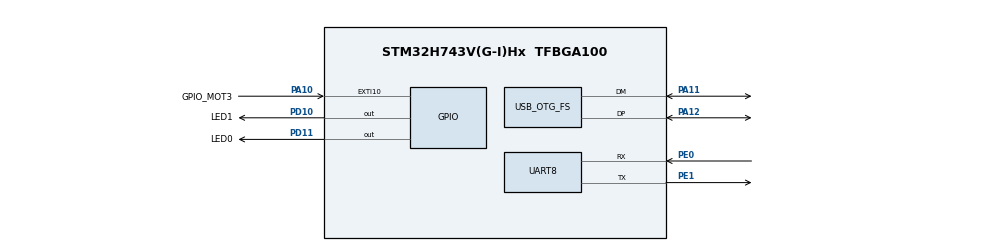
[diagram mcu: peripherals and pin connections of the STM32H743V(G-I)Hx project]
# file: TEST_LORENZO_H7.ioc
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CORTEX_M7.default_mode_Activation=1
Dma.Request0=UART8_RX
Dma.UART8_RX.0.Direction=DMA_PERIPH_TO_MEMORY
Dma.UART8_RX.0.EventEnable=DISABLE
Dma.UART8_RX.0.FIFOMode=DMA_FIFOMODE_DISABLE
Dma.UART8_RX.0.Instance=DMA1_Stream0
Dma.UART8_RX.0.MemDataAlignment=DMA_MDATAALIGN_BYTE
Dma.UART8_RX.0.MemInc=DMA_MINC_ENABLE
Dma.UART8_RX.0.Mode=DMA_CIRCULAR
Dma.UART8_RX.0.PeriphDataAlignment=DMA_PDATAALIGN_BYTE
Dma.UART8_RX.0.PeriphInc=DMA_PINC_DISABLE
Dma.UART8_RX.0.Polarity=HAL_DMAMUX_REQ_GEN_RISING
Dma.UART8_RX.0.Priority=DMA_PRIORITY_LOW
Dma.UART8_RX.0.RequestNumber=1
Dma.UART8_RX.0.SignalID=NONE
Dma.UART8_RX.0.SyncEnable=DISABLE
Dma.UART8_RX.0.SyncPolarity=HAL_DMAMUX_SYNC_NO_EVENT
Dma.UART8_RX.0.SyncRequestNumber=1
Dma.UART8_RX.0.SyncSignalID=NONE
FREERTOS.INCLUDE_uxTaskGetStackHighWaterMark2=1
FREERTOS.Tasks01=maintask,0,256,Startmaintask,Default,NULL,Dynamic,NULL,NULL;lidarparse,-3,500,Startlidarparse,Default,NULL,Dynamic,NULL,NULL
FREERTOS.configUSE_NEWLIB_REENTRANT=1
Mcu.Family=STM32H7
Mcu.Name=STM32H743V(G-I)Hx
Mcu.Package=TFBGA100
NVIC.DMA1_Stream0_IRQn=true\:5\:0\:false\:false\:true\:true\:false\:true\:true
NVIC.OTG_FS_IRQn=true\:5\:0\:false\:false\:true\:true\:false\:true\:true
NVIC.PriorityGroup=NVIC_PRIORITYGROUP_4
NVIC.TIM1_UP_IRQn=true\:15\:0\:false\:false\:true\:false\:false\:true\:true
NVIC.TimeBase=TIM1_UP_IRQn
NVIC.TimeBaseIP=TIM1
PA10.GPIO_Label=GPIO_MOT3
PA10.Signal=GPXTI10
PA11.Mode=Device_Only
PA11.Signal=USB_OTG_FS_DM
PA12.Mode=Device_Only
PA12.Signal=USB_OTG_FS_DP
PA13\ (JTMS/SWDIO).Mode=Serial_Wire
PA13\ (JTMS/SWDIO).Signal=DEBUG_JTMS-SWDIO
PA14\ (JTCK/SWCLK).Mode=Serial_Wire
PA14\ (JTCK/SWCLK).Signal=DEBUG_JTCK-SWCLK
PA15\ (JTDI).Signal=SPI1_NSS
PA8.Signal=I2C3_SCL
PB1.Signal=S_TIM3_CH4
PB10.Signal=I2C2_SCL
PB11.Signal=I2C2_SDA
PB14.Signal=USART1_TX
PB15.Signal=USART1_RX
PB3\ (JTDO/TRACESWO).Signal=SPI1_SCK
PB4\ (NJTRST).Signal=SPI1_MISO
PB7.Signal=S_TIM4_CH2
PB8.Signal=I2C1_SCL
PB9.Signal=I2C1_SDA
PC6.Signal=USART6_TX
PC7.Signal=USART6_RX
PC9.Signal=I2C3_SDA
PD0.Signal=SAI3_SCK_A
PD1.Signal=SAI3_SD_A
PD10.GPIO_Label=LED1
PD10.Signal=GPIO_Output
PD11.GPIO_Label=LED0
PD11.Signal=GPIO_Output
PD12.Signal=I2C4_SCL
PD13.Signal=I2C4_SDA
PD4.Signal=SAI3_FS_A
PD8.Signal=USART3_TX
PD9.Signal=USART3_RX
PE0.Mode=Asynchronous
PE0.Signal=UART8_RX
PE1.Mode=Asynchronous
PE1.Signal=UART8_TX
PE2.Signal=SPI4_SCK
PE5.Signal=SPI4_MISO
PE6.Signal=SPI4_MOSI
PE7.Signal=UART7_RX
PE8.Signal=UART7_TX
PH0-OSC_IN\ (PH0).Mode=HSE-External-Oscillator
PH0-OSC_IN\ (PH0).Signal=RCC_OSC_IN
PH1-OSC_OUT\ (PH1).Mode=HSE-External-Oscillator
PH1-OSC_OUT\ (PH1).Signal=RCC_OSC_OUT
ProjectManager.HeapSize=0x200
ProjectManager.StackSize=0x400
ProjectManager.TargetToolchain=STM32CubeIDE
RCC.ADCFreq_Value=75000000
RCC.APB1Freq_Value=120000000
RCC.APB2Freq_Value=120000000
RCC.APB3Freq_Value=120000000
RCC.APB4Freq_Value=120000000
RCC.CortexFreq_Value=480000000
RCC.D1PPRE=RCC_APB3_DIV2
RCC.D2PPRE1=RCC_APB1_DIV2
RCC.D2PPRE2=RCC_APB2_DIV2
RCC.D3PPRE=RCC_APB4_DIV2
RCC.DIVM1=1
RCC.DIVM2=8
RCC.DIVM3=2
RCC.DIVN1=120
RCC.DIVN2=150
RCC.DIVN3=130
RCC.DIVP3=10
RCC.HCLKFreq_Value=240000000
RCC.HPRE=RCC_HCLK_DIV2
RCC.HSE_VALUE=8000000
RCC.PLL2FRACN=0
RCC.PLL3FRACN=0
RCC.PLLFRACN=0
RCC.PLLSourceVirtual=RCC_PLLSOURCE_HSE
RCC.SAI23CLockSelection=RCC_SAI23CLKSOURCE_PLL2
RCC.SPI123CLockSelection=RCC_SPI123CLKSOURCE_PLL3
RCC.SYSCLKFreq_VALUE=480000000
RCC.SYSCLKSource=RCC_SYSCLKSOURCE_PLLCLK
RCC.USBCLockSelection=RCC_USBCLKSOURCE_HSI48
RCC.USBFreq_Value=48000000
SH.S_TIM3_CH4.0=TIM3_CH4
SH.S_TIM4_CH2.0=TIM4_CH2
USB_DEVICE.CLASS_NAME_FS=CDC
USB_DEVICE.VirtualMode-CDC_FS=Cdc
USB_DEVICE.VirtualModeFS=Cdc_FS
USB_OTG_FS.VirtualMode=Device_Only
VP_FREERTOS_VS_CMSIS_V1.Mode=CMSIS_V1
VP_MEMORYMAP_VS_MEMORYMAP.Mode=CurAppReg
VP_SYS_VS_tim1.Mode=TIM1
VP_USB_DEVICE_VS_USB_DEVICE_CDC_FS.Mode=CDC_FS
board=custom

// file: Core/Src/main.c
/* USER CODE BEGIN Header */
/**
  ******************************************************************************
  * @file           : main.c
  * @brief          : Main program body
  ******************************************************************************
  * @attention
  *
  * Copyright (c) 2025 STMicroelectronics.
  * All rights reserved.
  *
  * This software is licensed under terms that can be found in the LICENSE file
  * in the root directory of this software component.
  * If no LICENSE file comes with this software, it is provided AS-IS.
  *
  ******************************************************************************
  */
/* USER CODE END Header */
#include "main.h"
#include "cmsis_os.h"
#include "dma.h"
#include "usart.h"
#include "usb_device.h"
#include "gpio.h"

/* USER CODE BEGIN Includes */
#include "ylidar.h"
/* USER CODE END Includes */

/* USER CODE BEGIN PV */
extern uint8_t ylidar_circular_buffer[YLIDAR_CIRC_BUF_SIZE];
/* USER CODE END PV */

void SystemClock_Config(void);
static void MPU_Config(void);
void MX_FREERTOS_Init(void);

int main(void)
{

  /* MPU Configuration--------------------------------------------------------*/
  MPU_Config();

  /* MCU Configuration--------------------------------------------------------*/

  /* Reset of all peripherals, Initializes the Flash interface and the Systick. */
  HAL_Init();

  /* Configure the system clock */
  SystemClock_Config();

  /* Initialize all configured peripherals */
  MX_GPIO_Init();
  MX_DMA_Init();
  MX_UART8_Init();
  /* USER CODE BEGIN 2 */

  HAL_UART_Abort(&huart8);
  HAL_UART_Receive_DMA(&huart8, (uint8_t *)ylidar_circular_buffer, YLIDAR_CIRC_BUF_SIZE);
  __HAL_DMA_ENABLE_IT(huart8.hdmarx,DMA_IT_HT);

  /* USER CODE END 2 */

  /* Call init function for freertos objects (in cmsis_os2.c) */
  MX_FREERTOS_Init();

  /* Start scheduler */
  osKernelStart();

  /* We should never get here as control is now taken by the scheduler */

  /* Infinite loop */
  while (1)
  {

  }
}

void SystemClock_Config(void)
{
  RCC_OscInitTypeDef RCC_OscInitStruct = {0};
  RCC_ClkInitTypeDef RCC_ClkInitStruct = {0};

  /** Supply configuration update enable
  */
  HAL_PWREx_ConfigSupply(PWR_LDO_SUPPLY);

  /** Configure the main internal regulator output voltage
  */
  __HAL_PWR_VOLTAGESCALING_CONFIG(PWR_REGULATOR_VOLTAGE_SCALE0);

  while(!__HAL_PWR_GET_FLAG(PWR_FLAG_VOSRDY)) {}

  /** Initializes the RCC Oscillators according to the specified parameters
  * in the RCC_OscInitTypeDef structure.
  */
  RCC_OscInitStruct.OscillatorType = RCC_OSCILLATORTYPE_HSI48|RCC_OSCILLATORTYPE_HSE;
  RCC_OscInitStruct.HSEState = RCC_HSE_ON;
  RCC_OscInitStruct.HSI48State = RCC_HSI48_ON;
  RCC_OscInitStruct.PLL.PLLState = RCC_PLL_ON;
  RCC_OscInitStruct.PLL.PLLSource = RCC_PLLSOURCE_HSE;
  RCC_OscInitStruct.PLL.PLLM = 1;
  RCC_OscInitStruct.PLL.PLLN = 120;
  RCC_OscInitStruct.PLL.PLLP = 2;
  RCC_OscInitStruct.PLL.PLLQ = 2;
  RCC_OscInitStruct.PLL.PLLR = 2;
  RCC_OscInitStruct.PLL.PLLRGE = RCC_PLL1VCIRANGE_3;
  RCC_OscInitStruct.PLL.PLLVCOSEL = RCC_PLL1VCOWIDE;
  RCC_OscInitStruct.PLL.PLLFRACN = 0;
  if (HAL_RCC_OscConfig(&RCC_OscInitStruct) != HAL_OK)
  {
    Error_Handler();
  }

  /** Initializes the CPU, AHB and APB buses clocks
  */
  RCC_ClkInitStruct.ClockType = RCC_CLOCKTYPE_HCLK|RCC_CLOCKTYPE_SYSCLK
                              |RCC_CLOCKTYPE_PCLK1|RCC_CLOCKTYPE_PCLK2
                              |RCC_CLOCKTYPE_D3PCLK1|RCC_CLOCKTYPE_D1PCLK1;
  RCC_ClkInitStruct.SYSCLKSource = RCC_SYSCLKSOURCE_PLLCLK;
  RCC_ClkInitStruct.SYSCLKDivider = RCC_SYSCLK_DIV1;
  RCC_ClkInitStruct.AHBCLKDivider = RCC_HCLK_DIV2;
  RCC_ClkInitStruct.APB3CLKDivider = RCC_APB3_DIV2;
  RCC_ClkInitStruct.APB1CLKDivider = RCC_APB1_DIV2;
  RCC_ClkInitStruct.APB2CLKDivider = RCC_APB2_DIV2;
  RCC_ClkInitStruct.APB4CLKDivider = RCC_APB4_DIV2;

  if (HAL_RCC_ClockConfig(&RCC_ClkInitStruct, FLASH_LATENCY_4) != HAL_OK)
  {
    Error_Handler();
  }
}

 /* MPU Configuration */

void MPU_Config(void)
{
  MPU_Region_InitTypeDef MPU_InitStruct = {0};

  /* Disables the MPU */
  HAL_MPU_Disable();

  /** Initializes and configures the Region and the memory to be protected
  */
  MPU_InitStruct.Enable = MPU_REGION_ENABLE;
  MPU_InitStruct.Number = MPU_REGION_NUMBER0;
  MPU_InitStruct.BaseAddress = 0x0;
  MPU_InitStruct.Size = MPU_REGION_SIZE_4GB;
  MPU_InitStruct.SubRegionDisable = 0x87;
  MPU_InitStruct.TypeExtField = MPU_TEX_LEVEL0;
  MPU_InitStruct.AccessPermission = MPU_REGION_NO_ACCESS;
  MPU_InitStruct.DisableExec = MPU_INSTRUCTION_ACCESS_DISABLE;
  MPU_InitStruct.IsShareable = MPU_ACCESS_SHAREABLE;
  MPU_InitStruct.IsCacheable = MPU_ACCESS_NOT_CACHEABLE;
  MPU_InitStruct.IsBufferable = MPU_ACCESS_NOT_BUFFERABLE;

  HAL_MPU_ConfigRegion(&MPU_InitStruct);
  /* Enables the MPU */
  HAL_MPU_Enable(MPU_PRIVILEGED_DEFAULT);

}

void HAL_TIM_PeriodElapsedCallback(TIM_HandleTypeDef *htim)
{
  if (htim->Instance == TIM1)
  {
    HAL_IncTick();
  }
}

void Error_Handler(void)
{
  __disable_irq();
  while (1)
  {
  }
}

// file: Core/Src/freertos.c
/* USER CODE BEGIN Header */
/**
  ******************************************************************************
  * File Name          : freertos.c
  * Description        : Code for freertos applications
  ******************************************************************************
  * @attention
  *
  * Copyright (c) 2025 STMicroelectronics.
  * All rights reserved.
  *
  * This software is licensed under terms that can be found in the LICENSE file
  * in the root directory of this software component.
  * If no LICENSE file comes with this software, it is provided AS-IS.
  *
  ******************************************************************************
  */
/* USER CODE END Header */

#include "FreeRTOS.h"
#include "task.h"
#include "main.h"
#include "cmsis_os.h"

/* USER CODE BEGIN Includes */
#include "ylidar.h"
/* USER CODE END Includes */

/* USER CODE BEGIN Variables */
extern uint16_t ylidar_read_index;
extern uint16_t ylidar_write_index;

extern uint8_t ylidar_finalbuffer[1024];

/* USER CODE END Variables */
osThreadId maintaskHandle;
osThreadId lidarparseHandle;

void Startmaintask(void const * argument);
void Startlidarparse(void const * argument);

extern void MX_USB_DEVICE_Init(void);
void MX_FREERTOS_Init(void); /* (MISRA C 2004 rule 8.1) */

/* GetIdleTaskMemory prototype (linked to static allocation support) */
void vApplicationGetIdleTaskMemory( StaticTask_t **ppxIdleTaskTCBBuffer, StackType_t **ppxIdleTaskStackBuffer, uint32_t *pulIdleTaskStackSize );

/* USER CODE BEGIN GET_IDLE_TASK_MEMORY */
static StaticTask_t xIdleTaskTCBBuffer;
static StackType_t xIdleStack[configMINIMAL_STACK_SIZE];

void vApplicationGetIdleTaskMemory( StaticTask_t **ppxIdleTaskTCBBuffer, StackType_t **ppxIdleTaskStackBuffer, uint32_t *pulIdleTaskStackSize )
{
  *ppxIdleTaskTCBBuffer = &xIdleTaskTCBBuffer;
  *ppxIdleTaskStackBuffer = &xIdleStack[0];
  *pulIdleTaskStackSize = configMINIMAL_STACK_SIZE;
  /* place for user code */
}
/* USER CODE END GET_IDLE_TASK_MEMORY */

void MX_FREERTOS_Init(void) {

  /* Create the thread(s) */
  /* definition and creation of maintask */
  osThreadDef(maintask, Startmaintask, osPriorityNormal, 0, 256);
  maintaskHandle = osThreadCreate(osThread(maintask), NULL);

  /* definition and creation of lidarparse */
  osThreadDef(lidarparse, Startlidarparse, osPriorityIdle, 0, 500);
  lidarparseHandle = osThreadCreate(osThread(lidarparse), NULL);

}

void Startmaintask(void const * argument)
{
  /* init code for USB_DEVICE */
  MX_USB_DEVICE_Init();
  /* USER CODE BEGIN Startmaintask */
  /* Infinite loop */
  for(;;)
  {

	 //HAL_GPIO_TogglePin(GPIOE,GPIO_PIN_3);
	 //HAL_GPIO_TogglePin(GPIOE,GPIO_PIN_4);
	//CDC_Transmit_FS((uint8_t*) ylidar_finalbuffer, 721*sizeof(uint8_t));
    osDelay(1000);
  }
  /* USER CODE END Startmaintask */
}

void Startlidarparse(void const * argument)
{
  /* USER CODE BEGIN Startlidarparse */
  /* Infinite loop */
  for(;;)
  {
	  while (ylidar_read_index!=ylidar_write_index){
		  ylidar_fsm();
      }
	  trackObject();

	  osDelay(1);
  }
  /* USER CODE END Startlidarparse */
}
